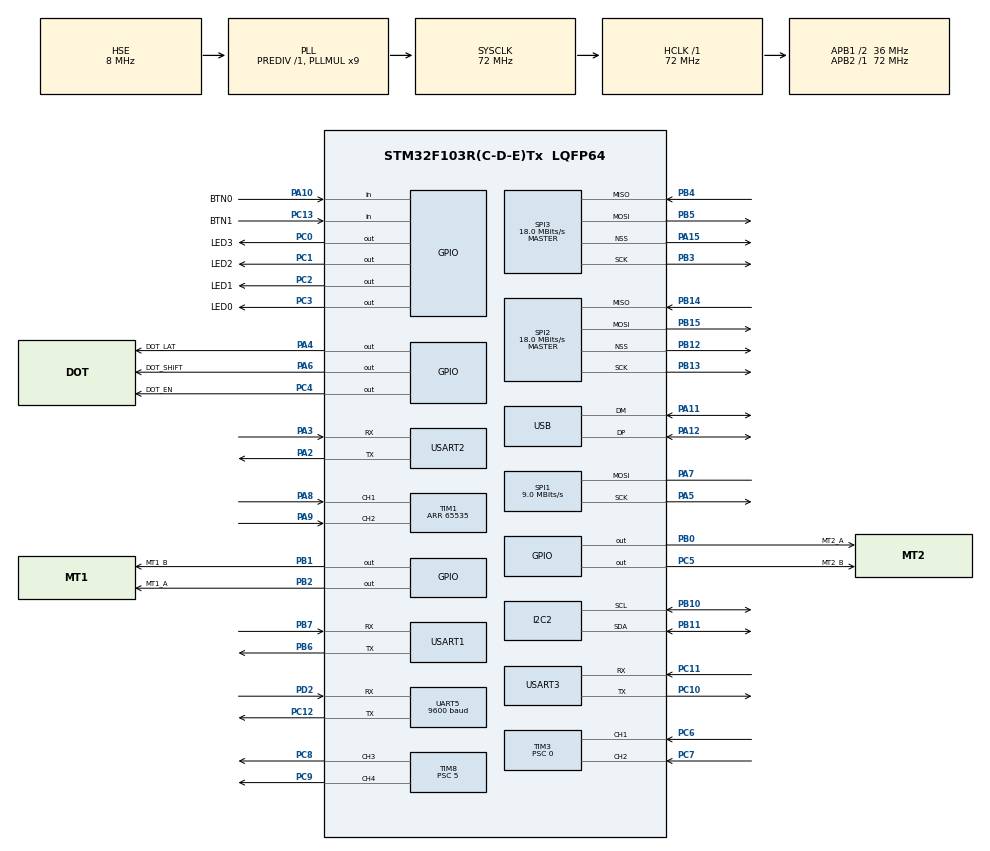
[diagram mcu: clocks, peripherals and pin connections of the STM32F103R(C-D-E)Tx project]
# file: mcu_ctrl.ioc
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Dma.I2C2_RX.0.Direction=DMA_PERIPH_TO_MEMORY
Dma.I2C2_RX.0.Instance=DMA1_Channel5
Dma.I2C2_RX.0.MemDataAlignment=DMA_MDATAALIGN_BYTE
Dma.I2C2_RX.0.MemInc=DMA_MINC_ENABLE
Dma.I2C2_RX.0.Mode=DMA_NORMAL
Dma.I2C2_RX.0.PeriphDataAlignment=DMA_PDATAALIGN_BYTE
Dma.I2C2_RX.0.PeriphInc=DMA_PINC_DISABLE
Dma.I2C2_RX.0.Priority=DMA_PRIORITY_LOW
Dma.Request0=I2C2_RX
I2C2.I2C_Mode=I2C_Fast
Mcu.Family=STM32F1
Mcu.Name=STM32F103R(C-D-E)Tx
Mcu.Package=LQFP64
NVIC.DMA1_Channel5_IRQn=true\:0\:0\:false\:false\:true\:false\:true
NVIC.PriorityGroup=NVIC_PRIORITYGROUP_4
NVIC.TIM5_IRQn=true\:3\:0\:true\:false\:true\:true\:true
NVIC.TIM6_IRQn=true\:1\:0\:true\:false\:true\:true\:true
NVIC.TIM7_IRQn=true\:2\:0\:true\:false\:true\:true\:true
NVIC.UART5_IRQn=true\:0\:0\:false\:false\:true\:true\:true
NVIC.USART1_IRQn=true\:0\:0\:false\:false\:true\:true\:true
NVIC.USART2_IRQn=true\:0\:0\:false\:false\:true\:true\:true
NVIC.USART3_IRQn=true\:0\:0\:false\:false\:true\:true\:true
PA10.GPIO_Label=BTN0
PA10.Signal=GPIO_Input
PA11.Mode=Device
PA11.Signal=USB_DM
PA12.Mode=Device
PA12.Signal=USB_DP
PA13.Mode=Serial_Wire
PA13.Signal=SYS_JTMS-SWDIO
PA14.Mode=Serial_Wire
PA14.Signal=SYS_JTCK-SWCLK
PA15.Mode=NSS_Signal_Hard_Output
PA15.Signal=SPI3_NSS
PA2.Mode=Asynchronous
PA2.Signal=USART2_TX
PA3.Mode=Asynchronous
PA3.Signal=USART2_RX
PA4.GPIO_Label=DOT_LAT
PA4.Signal=GPIO_Output
PA5.Mode=Simplex_Bidirectional_Master
PA5.Signal=SPI1_SCK
PA6.GPIO_Label=DOT_SHIFT
PA6.Signal=GPIO_Output
PA7.Mode=Simplex_Bidirectional_Master
PA7.Signal=SPI1_MOSI
PA8.Signal=S_TIM1_CH1
PA9.Signal=S_TIM1_CH2
PB0.GPIO_Label=MT2_A
PB0.Signal=GPIO_Output
PB1.GPIO_Label=MT1_B
PB1.Signal=GPIO_Output
PB10.Mode=I2C
PB10.Signal=I2C2_SCL
PB11.Mode=I2C
PB11.Signal=I2C2_SDA
PB12.Mode=NSS_Signal_Hard_Output
PB12.Signal=SPI2_NSS
PB13.Mode=Full_Duplex_Master
PB13.Signal=SPI2_SCK
PB14.Mode=Full_Duplex_Master
PB14.Signal=SPI2_MISO
PB15.Mode=Full_Duplex_Master
PB15.Signal=SPI2_MOSI
PB2.GPIO_Label=MT1_A
PB2.Signal=GPIO_Output
PB3.Mode=Full_Duplex_Master
PB3.Signal=SPI3_SCK
PB4.Mode=Full_Duplex_Master
PB4.Signal=SPI3_MISO
PB5.Mode=Full_Duplex_Master
PB5.Signal=SPI3_MOSI
PB6.Mode=Asynchronous
PB6.Signal=USART1_TX
PB7.Mode=Asynchronous
PB7.Signal=USART1_RX
PC0.GPIO_Label=LED3
PC0.Signal=GPIO_Output
PC1.GPIO_Label=LED2
PC1.Signal=GPIO_Output
PC10.Mode=Asynchronous
PC10.Signal=USART3_TX
PC11.Mode=Asynchronous
PC11.Signal=USART3_RX
PC12.Mode=Asynchronous
PC12.Signal=UART5_TX
PC13-TAMPER-RTC.GPIO_Label=BTN1
PC13-TAMPER-RTC.Signal=GPIO_Input
PC14-OSC32_IN.Mode=LSE-External-Oscillator
PC14-OSC32_IN.Signal=RCC_OSC32_IN
PC15-OSC32_OUT.Mode=LSE-External-Oscillator
PC15-OSC32_OUT.Signal=RCC_OSC32_OUT
PC2.GPIO_Label=LED1
PC2.Signal=GPIO_Output
PC3.GPIO_Label=LED0
PC3.Signal=GPIO_Output
PC4.GPIO_Label=DOT_EN
PC4.Signal=GPIO_Output
PC5.GPIO_Label=MT2_B
PC5.Signal=GPIO_Output
PC6.Signal=S_TIM3_CH1
PC7.Signal=S_TIM3_CH2
PC8.Signal=S_TIM8_CH3
PC9.Signal=S_TIM8_CH4
PD0-OSC_IN.Mode=HSE-External-Oscillator
PD0-OSC_IN.Signal=RCC_OSC_IN
PD1-OSC_OUT.Mode=HSE-External-Oscillator
PD1-OSC_OUT.Signal=RCC_OSC_OUT
PD2.Mode=Asynchronous
PD2.Signal=UART5_RX
ProjectManager.HeapSize=0x1000
ProjectManager.StackSize=0x1000
ProjectManager.TargetToolchain=SW4STM32
RCC.AHBFreq_Value=72000000
RCC.APB1CLKDivider=RCC_HCLK_DIV2
RCC.APB1Freq_Value=36000000
RCC.APB1TimFreq_Value=72000000
RCC.APB2Freq_Value=72000000
RCC.APB2TimFreq_Value=72000000
RCC.HCLKFreq_Value=72000000
RCC.PLLMUL=RCC_PLL_MUL9
RCC.SYSCLKFreq_VALUE=72000000
RCC.SYSCLKSource=RCC_SYSCLKSOURCE_PLLCLK
RCC.USBFreq_Value=48000000
RCC.USBPrescaler=RCC_USBCLKSOURCE_PLL_DIV1_5
SH.S_TIM1_CH1.0=TIM1_CH1,Encoder_Interface
SH.S_TIM1_CH2.0=TIM1_CH2,Encoder_Interface
SH.S_TIM3_CH1.0=TIM3_CH1,Encoder_Interface
SH.S_TIM3_CH2.0=TIM3_CH2,Encoder_Interface
SH.S_TIM8_CH3.0=TIM8_CH3,PWM Generation3 CH3
SH.S_TIM8_CH4.0=TIM8_CH4,PWM Generation4 CH4
SPI1.BaudRatePrescaler=SPI_BAUDRATEPRESCALER_8
SPI1.CLKPhase=SPI_PHASE_2EDGE
SPI1.CLKPolarity=SPI_POLARITY_HIGH
SPI1.CalculateBaudRate=9.0 MBits/s
SPI1.Direction=SPI_DIRECTION_1LINE
SPI1.Mode=SPI_MODE_MASTER
SPI1.VirtualType=VM_MASTER
SPI2.CalculateBaudRate=18.0 MBits/s
SPI2.Direction=SPI_DIRECTION_2LINES
SPI2.Mode=SPI_MODE_MASTER
SPI2.VirtualNSS=VM_NSSHARD
SPI2.VirtualType=VM_MASTER
SPI3.CalculateBaudRate=18.0 MBits/s
SPI3.Direction=SPI_DIRECTION_2LINES
SPI3.Mode=SPI_MODE_MASTER
SPI3.VirtualNSS=VM_NSSHARD
SPI3.VirtualType=VM_MASTER
TIM1.EncoderMode=TIM_ENCODERMODE_TI12
TIM1.Period=65535
TIM3.EncoderMode=TIM_ENCODERMODE_TI12
TIM3.Period=65535
TIM3.Prescaler=0
TIM5.Period=199
TIM5.Prescaler=35999
TIM6.Period=1
TIM6.Prescaler=35999
TIM7.Period=9
TIM7.Prescaler=35999
TIM8.Channel-PWM\ Generation3\ CH3=TIM_CHANNEL_3
TIM8.Channel-PWM\ Generation4\ CH4=TIM_CHANNEL_4
TIM8.Period=1999
TIM8.Prescaler=5
UART5.BaudRate=9600
UART5.VirtualMode=Asynchronous
USART1.VirtualMode=VM_ASYNC
USART2.VirtualMode=VM_ASYNC
USART3.VirtualMode=VM_ASYNC
VP_TIM5_VS_ClockSourceINT.Mode=Internal
VP_TIM6_VS_ClockSourceINT.Mode=Enable_Timer
VP_TIM7_VS_ClockSourceINT.Mode=Enable_Timer
board=custom

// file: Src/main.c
/* USER CODE BEGIN Header */
/**
  ******************************************************************************
  * @file           : main.c
  * @brief          : Main program body
  ******************************************************************************
  * @attention
  *
  * <h2><center>&copy; Copyright (c) 2020 STMicroelectronics.
  * All rights reserved.</center></h2>
  *
  * This software component is licensed by ST under BSD 3-Clause license,
  * the "License"; You may not use this file except in compliance with the
  * License. You may obtain a copy of the License at:
  *                        opensource.org/licenses/BSD-3-Clause
  *
  ******************************************************************************
  */
/* USER CODE END Header */
#include <stdio.h>
#include "main.h"
#include "dma.h"
#include "i2c.h"
#include "spi.h"
#include "tim.h"
#include "usart.h"
#include "usb.h"
#include "gpio.h"

/* USER CODE BEGIN Includes */
#include "common.h"
#include "esp8266.h"
#include "mpu6050.h"
#include "speed.h"

/* USER CODE END Includes */

void SystemClock_Config(void);

int main(void)
{

  /* MCU Configuration--------------------------------------------------------*/

  /* Reset of all peripherals, Initializes the Flash interface and the Systick. */
  HAL_Init();

  /* Configure the system clock */
  SystemClock_Config();

  /* Initialize all configured peripherals */
  MX_GPIO_Init();
  MX_I2C2_Init();
  MX_SPI1_Init();
  MX_SPI2_Init();
  MX_SPI3_Init();
  MX_TIM1_Init();
  MX_TIM3_Init();
  MX_TIM8_Init();
  MX_UART5_Init();
  MX_USART2_UART_Init();
  MX_USART3_UART_Init();
  MX_USB_PCD_Init();
  MX_DMA_Init();
  MX_USART1_UART_Init();
  MX_TIM6_Init();
  MX_TIM7_Init();
  MX_TIM5_Init();

  /* Infinite loop */
  /* USER CODE BEGIN WHILE */
  puts("\r");
  puts("\r");
  puts("\r");
  puts("==============================\r");
  puts("========= System up. =========\r");
  puts("==============================\r");
  esp8266_init_ap();
  SetWorkMode();
  while (1) {
    UserTask();
    // HAL_Delay(100);
    /* USER CODE END WHILE */

  }
}

void SystemClock_Config(void)
{
  RCC_OscInitTypeDef RCC_OscInitStruct = {0};
  RCC_ClkInitTypeDef RCC_ClkInitStruct = {0};
  RCC_PeriphCLKInitTypeDef PeriphClkInit = {0};

  /** Initializes the RCC Oscillators according to the specified parameters
  * in the RCC_OscInitTypeDef structure.
  */
  RCC_OscInitStruct.OscillatorType = RCC_OSCILLATORTYPE_HSE;
  RCC_OscInitStruct.HSEState = RCC_HSE_ON;
  RCC_OscInitStruct.HSEPredivValue = RCC_HSE_PREDIV_DIV1;
  RCC_OscInitStruct.HSIState = RCC_HSI_ON;
  RCC_OscInitStruct.PLL.PLLState = RCC_PLL_ON;
  RCC_OscInitStruct.PLL.PLLSource = RCC_PLLSOURCE_HSE;
  RCC_OscInitStruct.PLL.PLLMUL = RCC_PLL_MUL9;
  if (HAL_RCC_OscConfig(&RCC_OscInitStruct) != HAL_OK)
  {
    Error_Handler();
  }
  /** Initializes the CPU, AHB and APB buses clocks
  */
  RCC_ClkInitStruct.ClockType = RCC_CLOCKTYPE_HCLK|RCC_CLOCKTYPE_SYSCLK
                              |RCC_CLOCKTYPE_PCLK1|RCC_CLOCKTYPE_PCLK2;
  RCC_ClkInitStruct.SYSCLKSource = RCC_SYSCLKSOURCE_PLLCLK;
  RCC_ClkInitStruct.AHBCLKDivider = RCC_SYSCLK_DIV1;
  RCC_ClkInitStruct.APB1CLKDivider = RCC_HCLK_DIV2;
  RCC_ClkInitStruct.APB2CLKDivider = RCC_HCLK_DIV1;

  if (HAL_RCC_ClockConfig(&RCC_ClkInitStruct, FLASH_LATENCY_2) != HAL_OK)
  {
    Error_Handler();
  }
  PeriphClkInit.PeriphClockSelection = RCC_PERIPHCLK_USB;
  PeriphClkInit.UsbClockSelection = RCC_USBCLKSOURCE_PLL_DIV1_5;
  if (HAL_RCCEx_PeriphCLKConfig(&PeriphClkInit) != HAL_OK)
  {
    Error_Handler();
  }
}

void Error_Handler(void)
{
}

/************************ (C) COPYRIGHT STMicroelectronics *****END OF FILE****/
